# Musca_S1 register map
Vendor: ARM Ltd.; Series: ARMv8-M Mainline; File version: 1.0
CPU: CM33 r0p1, little endian, MPU, no FPU, 3 interrupt priority bits, 8 SAU regions
Registers are 32-bit, read-write, reset 0x0 unless marked. A register's access mark holds for its fields unless they carry their own. Offsets are from the block's base; [hi:lo] are bit positions; lines under a group give offsets from that group; {n}, {i} and the like mark numbered series.

## SCC — Serial Communication Controller
Base 0x4010C800
Same registers: SCC_Secure 0x5010C800
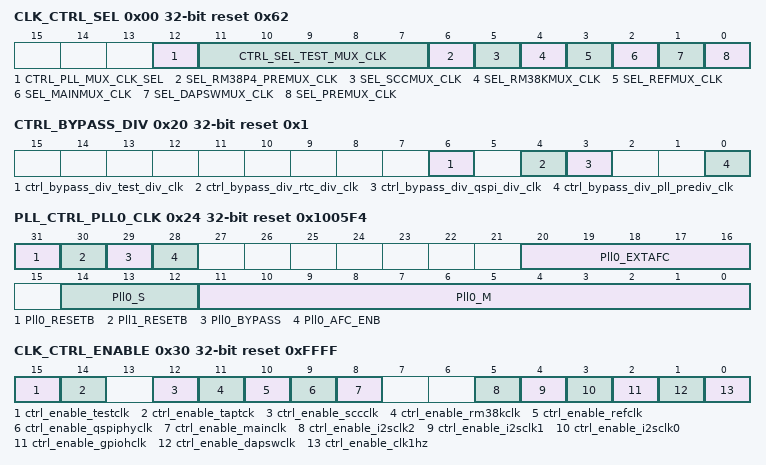
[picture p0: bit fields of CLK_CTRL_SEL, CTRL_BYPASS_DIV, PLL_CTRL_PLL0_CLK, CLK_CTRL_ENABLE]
0x00 CLK_CTRL_SEL reset 0x62 — Clock Control Select Register
  [12] CTRL_PLL_MUX_CLK_SEL — PLL MUX select: 0: PLL0, 1: Not used
  [11:7] CTRL_SEL_TEST_MUX_CLK — Select TESTMUX input
  [6] SEL_RM38P4_PREMUX_CLK — Select RM38KPREMUX input: 0: SYSSYSSUGCLK, 1: NRM138P4 (not used)
  [5] SEL_SCCMUX_CLK — Select SCCMUX input: 0: SCCCLK, 1: PRE_MUX_CLK
  [4] SEL_RM38KMUX_CLK — Select RM38KMUX input: 0: REF_MUX_CLK, 1: RM38K (not used)
  [3] SEL_REFMUX_CLK — Select REFMUX input: 0: PRE_MUX_CLK, 1: PRE_PLL_CLK
  [2] SEL_MAINMUX_CLK — Select MAINMUX input: 0: PLL0_CLK, 1: PRE_MUX_CLK
  [1] SEL_DAPSWMUX_CLK — Select DAPSWMUX input: 0: PRE_MUX_CLK, 1: JTAG TCK
  [0] SEL_PREMUX_CLK — Select PREMUX input: 0: 32K, 1: FASTCLK
0x04 CLK_PLL_PREDIV_CTRL — PLL Predivider Control Register
  [9:0] PREDIV_CTRL — PLL0 pre-divider value: Divison value = PREDIV_CTRL+1
0x08 CLK_BBGEN_DIV_CLK reset 0x28 — BBGEN Divider Clock
  [7:0] BBGEN_DIV — Bbgen divider value
0x10 CLK_POSTDIV_QSPI — QSPI Divider
  [7:0] postdiv_ctrl_qspi_div_clk — qspi_div_clk value
0x14 CLK_POSTDIV_RTC reset 0x7FFF — RTC Divider
  [31:0] postdiv_ctrl_rtc_div_clk — rtc_div_clk value
0x1C CLK_POSTDIV_TEST reset 0xA — Test Divider
  [7:0] postdiv_ctrl_test_div_clk — test_div_clk value
0x20 CTRL_BYPASS_DIV reset 0x1 — Bypass Divider Control Register
  [6] ctrl_bypass_div_test_div_clk — test_div_clk bypass value
  [4] ctrl_bypass_div_rtc_div_clk — rtc_div_clk bypass value
  [3] ctrl_bypass_div_qspi_div_clk — qspi_div_clk bypass value
  [0] ctrl_bypass_div_pll_prediv_clk — pll_prediv_clk bypass value
0x24 PLL_CTRL_PLL0_CLK reset 0x1005F4 — PLL0 Control Register
  [31] Pll0_RESETB — Power down
  [30] Pll1_RESETB — Power down
  [29] Pll0_BYPASS — bypass mode
  [28] Pll0_AFC_ENB — Monitoring pin
  [20:16] Pll0_EXTAFC — Monitoring pin
  [14:12] Pll0_S — Division value of the 3-bit programmable scaler
  [11:0] Pll0_M — Control pins to change the target frequency of internal oscillator
0x30 CLK_CTRL_ENABLE reset 0xFFFF — Clock Control Enable Register
  [15] ctrl_enable_testclk — test_div_clk enable
  [14] ctrl_enable_taptck — tck_mux_clk enable
  [12] ctrl_enable_sccclk — scc_mux_clk enable
  [11] ctrl_enable_rm38kclk — rm38k_mux_clk enable
  [10] ctrl_enable_refclk — ref_mux_clk enable
  [9] ctrl_enable_qspiphyclk — qspi_div_clk enable
  [8] ctrl_enable_mainclk — main_mux_clk enable
  [5] ctrl_enable_i2sclk2 — I_SYSSYSUGCLK enable
  [4] ctrl_enable_i2sclk1 — I_SYSSYSUGCLK enable
  [3] ctrl_enable_i2sclk0 — I_SYSSYSUGCLK enable
  [2] ctrl_enable_gpiohclk — I_SYSSYSUGCLK enable
  [1] ctrl_enable_dapswclk — dapsw_mux_clk enable
  [0] ctrl_enable_clk1hz — rtc_div_clk enable
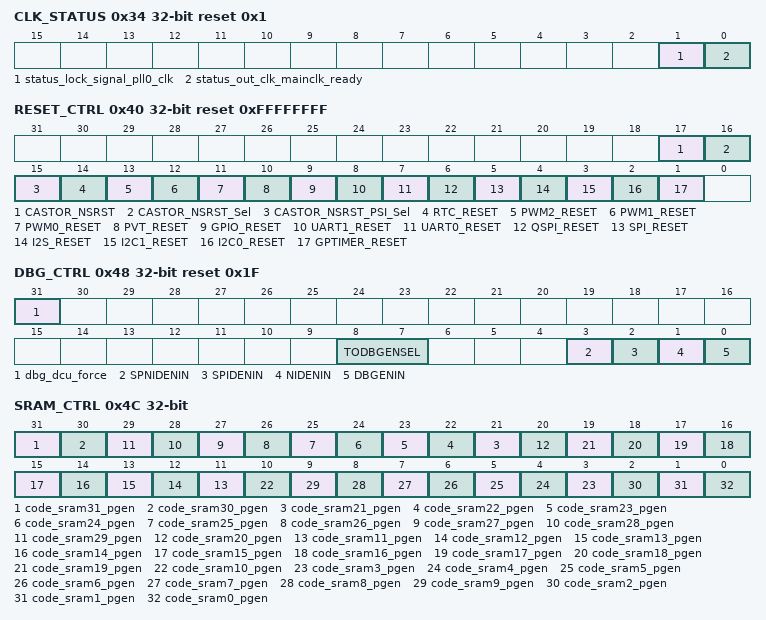
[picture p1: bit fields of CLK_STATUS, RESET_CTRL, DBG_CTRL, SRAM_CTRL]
0x34 CLK_STATUS ro reset 0x1 — Clock Status Register
  [1] status_lock_signal_pll0_clk — PLL Lock Status
  [0] status_out_clk_mainclk_ready — Clock ready (active)
0x40 RESET_CTRL reset 0xFFFFFFFF — Reset Control Register
  [17] CASTOR_NSRST — Reset Active low
  [16] CASTOR_NSRST_Sel — Reset Active low
  [15] CASTOR_NSRST_PSI_Sel — Reset Active low
  [14] RTC_RESET — Reset Active low
  [13] PWM2_RESET — Reset Active low
  [12] PWM1_RESET — Reset Active low
  [11] PWM0_RESET — Reset Active low
  [10] PVT_RESET — Reset Active low
  [9] GPIO_RESET — Reset Active low
  [8] UART1_RESET — Reset Active low
  [7] UART0_RESET — Reset Active low
  [6] QSPI_RESET — Reset Active low
  [5] SPI_RESET — Reset Active low
  [4] I2S_RESET — Reset Active low
  [3] I2C1_RESET — Reset Active low
  [2] I2C0_RESET — Reset Active low
  [1] GPTIMER_RESET — Reset Active low
0x48 DBG_CTRL reset 0x1F — Debug Control Register
  [31] dbg_dcu_force — Castor DBG ports control 0: use Crypto DCU 1: Use SCC signals (force)
  [8:7] TODBGENSEL — Debug expansion TODBGENSEL
  [3] SPNIDENIN — Castor SPNIDENIN
  [2] SPIDENIN — Castor SPIDENIN
  [1] NIDENIN — Castor NIDENIN
  [0] DBGENIN — Castor DBGENIN
0x4C SRAM_CTRL — SRAM Control Register
  [31] code_sram31_pgen — 32th 64KB Code SRAM cell power gate enable
  [30] code_sram30_pgen — 31st 64KB Code SRAM cell power gate enable
  [n] code_sram{n}_pgen (n=21..29) — {n+1}th 64KB Code SRAM cell power gate enable
  [20] code_sram20_pgen — 21st 64KB Code SRAM cell power gate enable
  [n] code_sram{n}_pgen (n=11..19) — {n+1}th 64KB Code SRAM cell power gate enable
  [10] code_sram10_pgen — 11st 64KB Code SRAM cell power gate enable
  [n] code_sram{n}_pgen (n=3..9) — {n+1}th 64KB Code SRAM cell power gate enable
  [2] code_sram2_pgen — 3rd 64KB Code SRAM cell power gate enable
  [1] code_sram1_pgen — 2nd 64KB Code SRAM cell power gate enable
  [0] code_sram0_pgen — 1st 64KB Code SRAM cell power gate enable
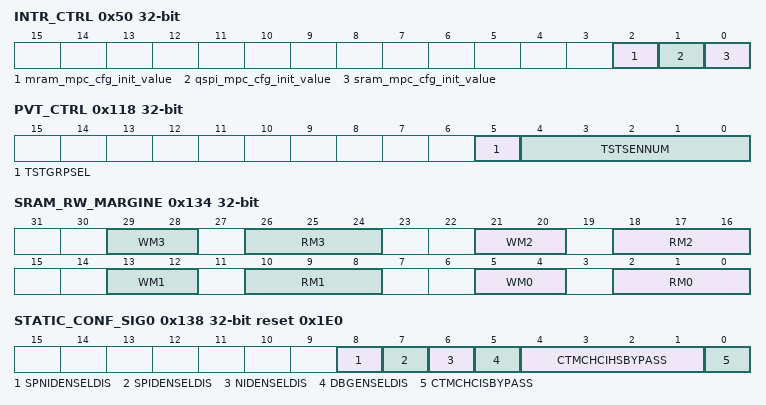
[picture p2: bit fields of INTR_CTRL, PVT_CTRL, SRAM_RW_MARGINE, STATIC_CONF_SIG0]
0x50 INTR_CTRL — MPC Interrupt Control Register
  [2] mram_mpc_cfg_init_value, [1] qspi_mpc_cfg_init_value, [0] sram_mpc_cfg_init_value
0x58 CPU0_VTOR reset 0x10000000
0x5C CPU0_VTOR_1 reset 0x1A000000
0x60 CPU1_VTOR reset 0x10000000 — CPU 1 VTROR Register
0x64 CPU1_VTOR_1 reset 0x1A000000
0x68 IOMUX_MAIN_INSEL reset 0xFFFFFFFF — IOMux Main Function Input Data Select Register
0x70 IOMUX_MAIN_OUTSEL reset 0xFFFFFFFF — IOMux Main Function Output Data Select Register
0x78 IOMUX_MAIN_OENSEL reset 0xFFFFFFFF — IOMux Main Function Output Enable Select Register
0x80 IOMUX_MAIN_DEFAULT_IN — IOMux Main Function Input Default Data Register
{0x68+0x20*i} IOMUX_ALTF{i}_INSEL (i=1..3) — IOMux Alternate Function {i} Input Data Select Register
{0x70+0x20*i} IOMUX_ALTF{i}_OUTSEL reset 0xFFFFFFFF (i=1..3) — IOMux Alternate Function {i} Output Data Select Register
{0x78+0x20*i} IOMUX_ALTF{i}_OENSEL reset 0xFFFFFFFF (i=1..3) — IOMux Alternate Function {i} Output Enable Select Register
{0x80+0x20*i} IOMUX_ALTF{i}_DEFAULT_IN (i=1..3) — IOMux Alternate Function 1 Input Default Data Register
0xE8 IOPAD_DS0 reset 0xFFFFFFFF — IO Pad Drive Select 0 Register
0xF0 IOPAD_DS1 reset 0xFFFFFFFF — IO Pad Drive Select 1 Register
0xF8 IOPAD_PE reset 0xFFFFFFFF — IO Pad Pull Enable Register
0x100 IOPAD_PS reset 0xFC1FFFFF — IO Pad Pull Select Register
0x108 IOPAD_SR — IO Pad Slew Rate Register
0x110 IOPAD_IS reset 0xFFFFFFFF — IO Pad Input Mode Select Register
0x118 PVT_CTRL — PVT Control Register
  [5] TSTGRPSEL — Test group select
  [4:0] TSTSENNUM — Test SEN number
0x134 SRAM_RW_MARGINE — SRAM Read/Write Margin Control Register
  [8n+5:8n+4] WM{n} (n=0..3) — Write margin control for code srams: u_sram_64k_{8n} .. u_sram_64k_{8n+7}
  [8n+2:8n] RM{n} (n=0..3) — Read margin control for code srams: u_sram_64k_{8n} .. u_sram_64k_{8n+7}
0x138 STATIC_CONF_SIG0 reset 0x1E0
  [8] SPNIDENSELDIS — SPNIDEN Selector Disable
  [7] SPIDENSELDIS — SPIDEN Selector Disable
  [6] NIDENSELDIS — NIDEN Selector Disable
  [5] DBGENSELDIS — DBGEN Selector Disable
  [4:1] CTMCHCIHSBYPASS — Cross Trigger Channel Interface Configuarion
  [0] CTMCHCISBYPASS — Cross Trigger Channel Interface Configuration
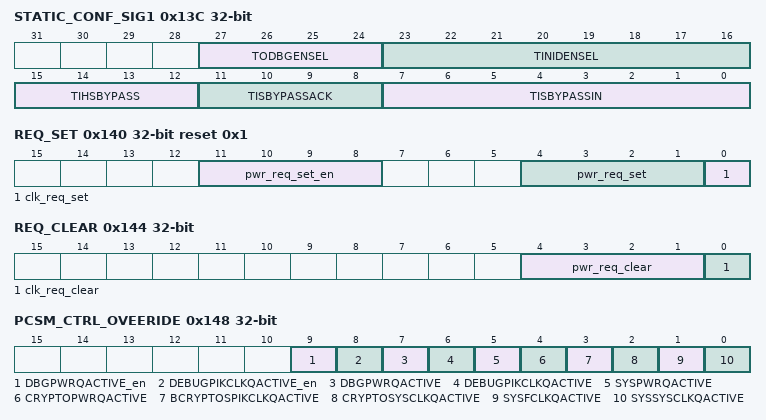
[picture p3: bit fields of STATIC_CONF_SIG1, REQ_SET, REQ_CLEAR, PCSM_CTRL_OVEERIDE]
0x13C STATIC_CONF_SIG1
  [27:24] TODBGENSEL — DBGEN mask on CTITRIGOUT
  [23:16] TINIDENSEL — NIDEN mask on CTITRIGINT
  [15:12] TIHSBYPASS — Cross Trigger interface handshake bypass on CTITRIGOUT
  [11:8] TISBYPASSACK — Cross Trigger Interface synchronous bypass on CTITRIGOUTACK
  [7:0] TISBYPASSIN — Cross Trigger Interface synchronous bypass on CTITRIGIN
0x140 REQ_SET reset 0x1 — Clock and Power Request Set Register
  [11:8] pwr_req_set_en — External event enable
  [4:1] pwr_req_set — Set SYSPOWERREQUEST
  [0] clk_req_set — Set SYSMAINCLKREQUEST
0x144 REQ_CLEAR — Clock and Power Request Clear Register
  [4:1] pwr_req_clear — Power request clear
  [0] clk_req_clear — Clock request clear
0x148 PCSM_CTRL_OVEERIDE — PCSM Control Override Register
  [9] DBGPWRQACTIVE_en — Q-Channels QACTIVE Override
  [8] DEBUGPIKCLKQACTIVE_en — Q-Channels QACTIVE Override
  [7] DBGPWRQACTIVE — Q-Channels QACTIVE Override
  [6] DEBUGPIKCLKQACTIVE — Q-Channels QACTIVE Override
  [5] SYSPWRQACTIVE — Q-Channels QACTIVE Override
  [4] CRYPTOPWRQACTIVE — Q-Channels QACTIVE Override
  [3] BCRYPTOSPIKCLKQACTIVE — Q-Channels QACTIVE Override
  [2] CRYPTOSYSCLKQACTIVE — Q-Channels QACTIVE Override
  [1] SYSFCLKQACTIVE — Q-Channels QACTIVE Override
  [0] SYSSYSCLKQACTIVE — Q-Channels QACTIVE Override
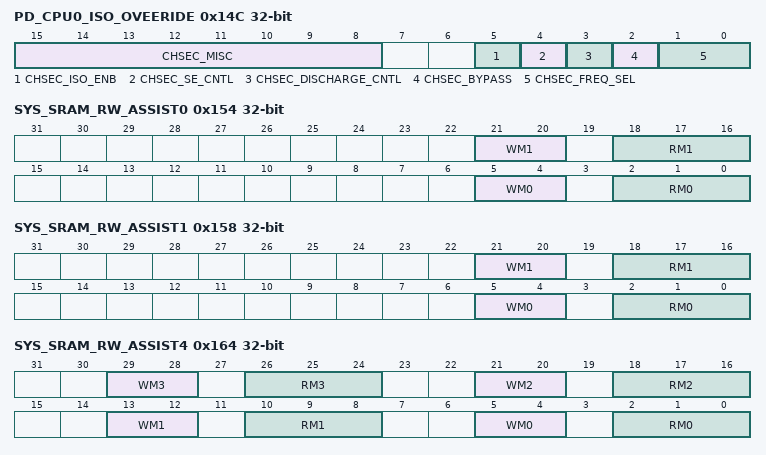
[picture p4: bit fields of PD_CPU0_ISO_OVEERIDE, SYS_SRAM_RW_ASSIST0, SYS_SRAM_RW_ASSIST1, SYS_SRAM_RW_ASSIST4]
0x14C PD_CPU0_ISO_OVEERIDE
  [15:8] CHSEC_MISC — Secure Frame Control
  [5] CHSEC_ISO_ENB — Secure Frame Isolation Enable
  [4] CHSEC_SE_CNTL — Secure Frame Scan Enable control
  [3] CHSEC_DISCHARGE_CNTL — Secure Frame discharge control
  [2] CHSEC_BYPASS — Secure Frame Bypass
  [1:0] CHSEC_FREQ_SEL — Secure Frame Frequency select
0x150 PD_CPU1_ISO_OVEERIDE — CPU1 Isolation Override Register
0x154 SYS_SRAM_RW_ASSIST0 — CPU0 SRAM Read/Write Margin Control Register
  [21:20] WM1 — Castor cpu0 tag_sram_1 write margin
  [18:16] RM1 — Castor cpu0 tag_sram_1 read margin
  [5:4] WM0 — Castor cpu0 tag_sram_0 write margin
  [2:0] RM0 — Castor cpu0 tag_sram_0 read margin
0x158 SYS_SRAM_RW_ASSIST1 — CPU1 SRAM Read/Write Margin Control Register
  [21:20] WM1 — Castor cpu1 tag_sram_1 write margin
  [18:16] RM1 — Castor cpu1 tag_sram_1 read margin
  [5:4] WM0 — Castor cpu1 tag_sram_0 write margin
  [2:0] RM0 — Castor cpu1 tag_sram_0 read margin
0x164 SYS_SRAM_RW_ASSIST4 — Core 0/1 SRAM Read/Write Margin Control Register
  [29:28] WM3 — Castor core_1 sram_1 write margin
  [26:24] RM3 — Castor core_1 sram_1 read margin
  [21:20] WM2 — Castor core_1 sram_0 write margin
  [18:16] RM2 — Castor core_1 sram_0 read margin
  [13:12] WM1 — Castor core_0 sram_1 write margin
  [10:8] RM1 — Castor core_0 sram_1 read margin
  [5:4] WM0 — Castor core_0 sram_0 write margin
  [2:0] RM0 — Castor core_0 sram_0 read margin
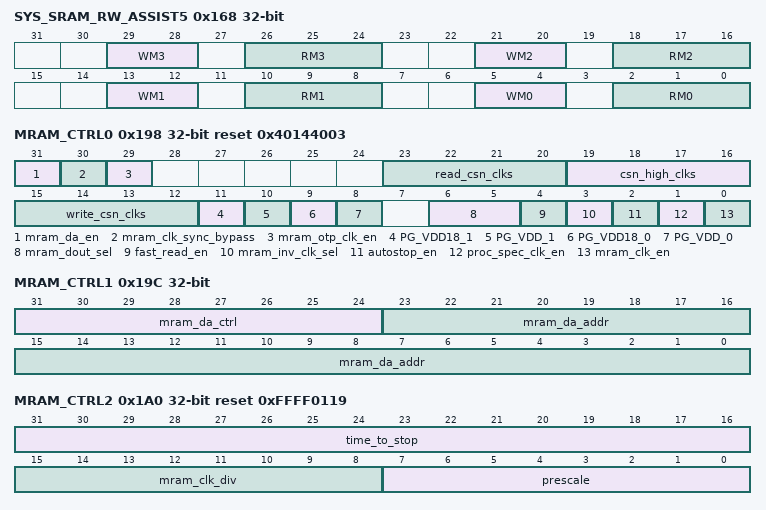
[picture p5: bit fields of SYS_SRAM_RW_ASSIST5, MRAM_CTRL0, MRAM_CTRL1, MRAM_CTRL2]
0x168 SYS_SRAM_RW_ASSIST5 — Core 2/3 SRAM Read/Write Margin Control Register
  [29:28] WM3 — Castor core_3 sram_1 write margin
  [26:24] RM3 — Castor core_3 sram_1 read margin
  [21:20] WM2 — Castor core_3 sram_0 write margin
  [18:16] RM2 — Castor core_3 sram_0 read margin
  [13:12] WM1 — Castor core_2 sram_1 write margin
  [10:8] RM1 — Castor core_2 sram_1 read margin
  [5:4] WM0 — Castor core_2 sram_0 write margin
  [2:0] RM0 — Castor core_2 sram_0 read margin
0x184 REQ_EDGE_SEL — Clock and Power Request Edge Select Register
0x188 REQ_ENABLE — Clock and Power Request Enable Register
0x198 MRAM_CTRL0 reset 0x40144003 — eMRAM Control 0 Register
  [31] mram_da_en — eMRAM direct access enable
  [30] mram_clk_sync_bypass — eMRAM clock sync bypass
  [29] mram_otp_clk_en — eMRAM OTP clock enable
  [23:20] read_csn_clks — Number of clocks cycles for single read operation
  [19:16] csn_high_clks — Number of clock cycles to wait when CSN is high before going to new access
  [15:12] write_csn_clks — Number of clock cycles for single write operation
  [11] PG_VDD18_1 — eMRAM1 PG VDD18
  [10] PG_VDD_1 — eMRAM1 PG VDD
  [9] PG_VDD18_0 — eMRAM0 PG VDD18
  [8] PG_VDD_0 — eMRAM0 PG VDD
  [6:5] mram_dout_sel — eMRAM data out select
  [4] fast_read_en — Fast read enable
  [3] mram_inv_clk_sel — eMRAM clock invert select
  [2] autostop_en — Auto stop enable
  [1] proc_spec_clk_en — eMRAM controller clock enable
  [0] mram_clk_en — eMRAM clock enable
0x19C MRAM_CTRL1 — eMRAM Control 1 Register
  [31:24] mram_da_ctrl — eMRAM direct access controls
  [23:0] mram_da_addr — eMRAM direct access address
0x1A0 MRAM_CTRL2 reset 0xFFFF0119 — eMRAM Control 2 Register
  [31:16] time_to_stop — Number of useconds to wait in inactive mode before going to STOP mode if auto_stop is enabled
  [15:8] mram_clk_div — eMRAM clock divider
  [7:0] prescale — eMRAM clock frequency value
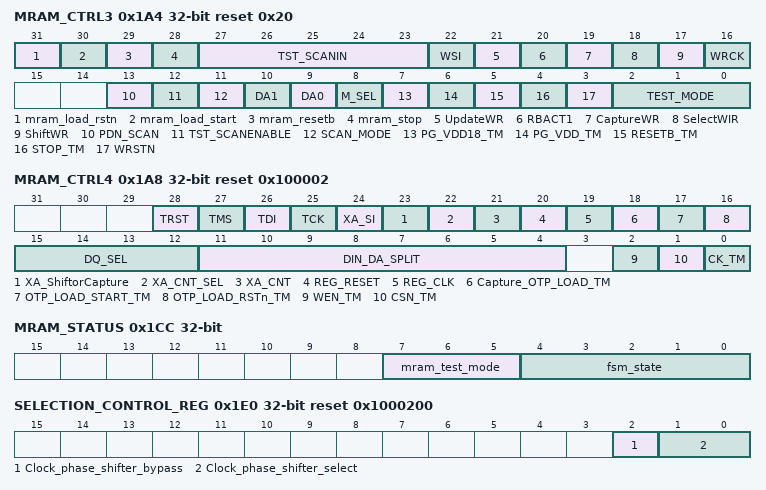
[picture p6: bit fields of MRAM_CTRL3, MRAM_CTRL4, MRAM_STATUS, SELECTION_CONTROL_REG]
0x1A4 MRAM_CTRL3 reset 0x20 — eMRAM Control 3 Register
  [31] mram_load_rstn — Access by SCC at functional mode
  [30] mram_load_start — Access by SCC at functional mode
  [29] mram_resetb — Access by SCC at functional mode
  [28] mram_stop — Access by SCC at functional mode
  [27:23] TST_SCANIN — Access by SCC at functional mode
  [22] WSI — Access by SCC at functional mode
  [21] UpdateWR — Access by SCC at functional mode
  [20] RBACT1 — Access by SCC at functional mode
  [19] CaptureWR — Access by SCC at functional mode
  [18] SelectWIR — Access by SCC at functional mode
  [17] ShiftWR — Access by SCC at functional mode
  [16] WRCK — Access by SCC at functional mode
  [13] PDN_SCAN — Access by SCC at functional mode
  [12] TST_SCANENABLE — Access by SCC at functional mode
  [11] SCAN_MODE — Access by SCC at functional mode
  [10] DA1 — Access by SCC at functional mode
  [9] DA0 — Access by SCC at functional mode
  [8] M_SEL — Access by SCC at functional mode
  [7] PG_VDD18_TM — Access by SCC at functional mode
  [6] PG_VDD_TM — Access by SCC at functional mode
  [5] RESETB_TM — Access by SCC at functional mode
  [4] STOP_TM — Access by SCC at functional mode
  [3] WRSTN — Access by SCC at functional mode
  [2:0] TEST_MODE — Access by SCC at functional mode
0x1A8 MRAM_CTRL4 reset 0x100002 — eMRAM Control 4 Register
  [28] TRST — Access by SCC at functional mode
  [27] TMS — Access by SCC at functional mode
  [26] TDI — Access by SCC at functional mode
  [25] TCK — Access by SCC at functional mode
  [24] XA_SI — Access by SCC at functional mode
  [23] XA_ShiftorCapture — Access by SCC at functional mode
  [22] XA_CNT_SEL — Access by SCC at functional mode
  [21] XA_CNT — Access by SCC at functional mode
  [20] REG_RESET — Access by SCC at functional mode
  [19] REG_CLK — Access by SCC at functional mode
  [18] Capture_OTP_LOAD_TM — Access by SCC at functional mode
  [17] OTP_LOAD_START_TM — Access by SCC at functional mode
  [16] OTP_LOAD_RSTn_TM — Access by SCC at functional mode
  [15:12] DQ_SEL — Access by SCC at functional mode
  [11:4] DIN_DA_SPLIT — Access by SCC at functional mode
  [2] WEN_TM — Access by SCC at functional mode
  [1] CSN_TM — Access by SCC at functional mode
  [0] CK_TM — Access by SCC at functional mode
0x1B0 MRAM_DIN0 — eMRAM input data mram_din[31:0]
0x1B4 MRAM_DIN1 — eMRAM input data mram_din[63:32]
0x1B8 MRAM_DIN2 — eMRAM input data mram_din[77:64]
0x1C0 MRAM_DOUT0 ro — eMRAM output data mram_dout[31:0]
0x1C4 MRAM_DOUT1 ro — eMRAM output data mram_dout[63:32]
0x1C8 MRAM_DOUT2 ro — eMRAM output data mram_dout[77:64]
0x1CC MRAM_STATUS ro — eMRAM Status Register
  [7:5] mram_test_mode — eMRAM test mode
  [4:0] fsm_state — eMRAM controller FSM state
0x1E0 SELECTION_CONTROL_REG reset 0x1000200 — Selection Control Register
  [2] Clock_phase_shifter_bypass, [1:0] Clock_phase_shifter_select
0x200 AZ_CTRL — AZ Control Register
  [9] SCC_nPORESETAON_nPORESET_SEL — Memory subsystem reset select: 1: nPORESETAON 0: NPORESET
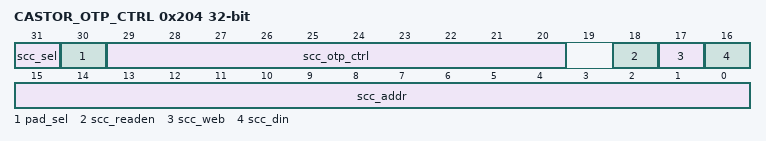
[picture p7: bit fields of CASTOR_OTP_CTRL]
0x204 CASTOR_OTP_CTRL — OTP Control Register
  [31] scc_sel — OTP control selection
  [30] pad_sel — OTP control selection
  [29:20] scc_otp_ctrl — scc otp control
  [18] scc_readen — readen from scc
  [17] scc_web — web from scc
  [16] scc_din — din from scc
  [15:0] scc_addr — otp addr from scc
0x220 BBGEN_CTRL — Body Bias Enable Control Register
0x224 SPARE_CTRL1 — Spare 1 Control Register
0x400 CHIP_ID ro reset 0x7990477
0x404 IO_IN_STATUS ro reset 0x13FFFFF — GP IO Pads Input Status Register
